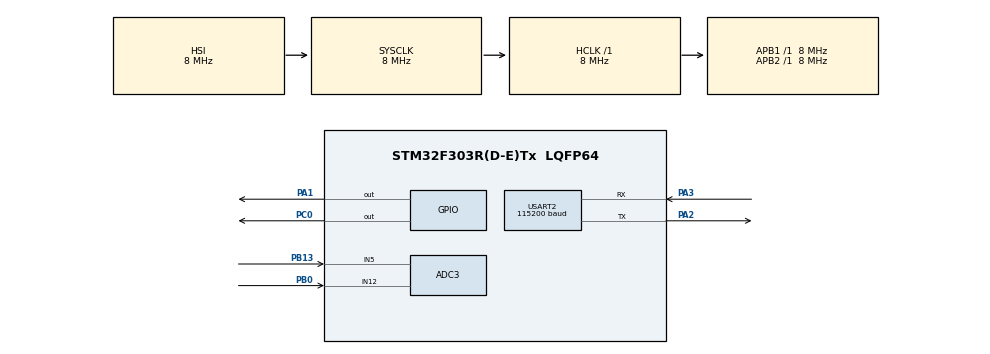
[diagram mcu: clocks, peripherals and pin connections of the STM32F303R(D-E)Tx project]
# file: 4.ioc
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ADC3.Channel-0\#ChannelRegularConversion=ADC_CHANNEL_12
ADC3.Channel-1\#ChannelRegularConversion=ADC_CHANNEL_5
ADC3.ContinuousConvMode=ENABLE
ADC3.DMAContinuousRequests=ENABLE
ADC3.NbrOfConversion=2
ADC3.NbrOfConversionFlag=1
ADC3.Offset-0\#ChannelRegularConversion=0
ADC3.Offset-1\#ChannelRegularConversion=0
ADC3.OffsetNumber-0\#ChannelRegularConversion=ADC_OFFSET_NONE
ADC3.OffsetNumber-1\#ChannelRegularConversion=ADC_OFFSET_NONE
ADC3.Rank-0\#ChannelRegularConversion=1
ADC3.Rank-1\#ChannelRegularConversion=2
ADC3.SamplingTime-0\#ChannelRegularConversion=ADC_SAMPLETIME_1CYCLE_5
ADC3.SamplingTime-1\#ChannelRegularConversion=ADC_SAMPLETIME_1CYCLE_5
ADC3.master=1
Dma.ADC3.0.Direction=DMA_PERIPH_TO_MEMORY
Dma.ADC3.0.Instance=DMA2_Channel5
Dma.ADC3.0.MemDataAlignment=DMA_MDATAALIGN_WORD
Dma.ADC3.0.MemInc=DMA_MINC_ENABLE
Dma.ADC3.0.Mode=DMA_CIRCULAR
Dma.ADC3.0.PeriphDataAlignment=DMA_PDATAALIGN_WORD
Dma.ADC3.0.PeriphInc=DMA_PINC_DISABLE
Dma.ADC3.0.Priority=DMA_PRIORITY_LOW
Dma.Request0=ADC3
Mcu.Family=STM32F3
Mcu.Name=STM32F303R(D-E)Tx
Mcu.Package=LQFP64
NVIC.DMA2_Channel5_IRQn=true\:0\:0\:false\:false\:true\:false
NVIC.PriorityGroup=NVIC_PRIORITYGROUP_4
PA1.Signal=GPIO_Output
PA2.Mode=Asynchronous
PA2.Signal=USART2_TX
PA3.Mode=Asynchronous
PA3.Signal=USART2_RX
PB0.Mode=IN12-Single-Ended
PB0.Signal=ADC3_IN12
PB13.Mode=IN5-Single-Ended
PB13.Signal=ADC3_IN5
PC0.PinState=GPIO_PIN_SET
PC0.Signal=GPIO_Output
ProjectManager.HeapSize=0x200
ProjectManager.StackSize=0x400
ProjectManager.TargetToolchain=TrueSTUDIO
RCC.ADC12PRES=RCC_ADC12PLLCLK_DIV2
RCC.ADC34PRES=RCC_ADC34PLLCLK_DIV2
RCC.AHBFreq_Value=8000000
RCC.APB1Freq_Value=8000000
RCC.APB2Freq_Value=8000000
RCC.CortexFreq_Value=8000000
RCC.HSE_VALUE=8000000
RCC.HSI_VALUE=8000000
RCC.LSE_VALUE=32768
RCC.SYSCLKFreq_VALUE=8000000
RCC.USBFreq_Value=16000000
USART2.BaudRate=115200
USART2.VirtualMode-Asynchronous=VM_ASYNC
USART2.WordLength=WORDLENGTH_8B
board=4

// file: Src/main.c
/**
  ******************************************************************************
  * @file           : main.c
  * @brief          : Main program body
  ******************************************************************************
  ** This notice applies to any and all portions of this file
  * that are not between comment pairs USER CODE BEGIN and
  * USER CODE END. Other portions of this file, whether
  * inserted by the user or by software development tools
  * are owned by their respective copyright owners.
  *
  * COPYRIGHT(c) 2018 STMicroelectronics
  *
  * Redistribution and use in source and binary forms, with or without modification,
  * are permitted provided that the following conditions are met:
  *   1. Redistributions of source code must retain the above copyright notice,
  *      this list of conditions and the following disclaimer.
  *   2. Redistributions in binary form must reproduce the above copyright notice,
  *      this list of conditions and the following disclaimer in the documentation
  *      and/or other materials provided with the distribution.
  *   3. Neither the name of STMicroelectronics nor the names of its contributors
  *      may be used to endorse or promote products derived from this software
  *      without specific prior written permission.
  *
  * THIS SOFTWARE IS PROVIDED BY THE COPYRIGHT HOLDERS AND CONTRIBUTORS "AS IS"
  * AND ANY EXPRESS OR IMPLIED WARRANTIES, INCLUDING, BUT NOT LIMITED TO, THE
  * IMPLIED WARRANTIES OF MERCHANTABILITY AND FITNESS FOR A PARTICULAR PURPOSE ARE
  * DISCLAIMED. IN NO EVENT SHALL THE COPYRIGHT HOLDER OR CONTRIBUTORS BE LIABLE
  * FOR ANY DIRECT, INDIRECT, INCIDENTAL, SPECIAL, EXEMPLARY, OR CONSEQUENTIAL
  * DAMAGES (INCLUDING, BUT NOT LIMITED TO, PROCUREMENT OF SUBSTITUTE GOODS OR
  * SERVICES; LOSS OF USE, DATA, OR PROFITS; OR BUSINESS INTERRUPTION) HOWEVER
  * CAUSED AND ON ANY THEORY OF LIABILITY, WHETHER IN CONTRACT, STRICT LIABILITY,
  * OR TORT (INCLUDING NEGLIGENCE OR OTHERWISE) ARISING IN ANY WAY OUT OF THE USE
  * OF THIS SOFTWARE, EVEN IF ADVISED OF THE POSSIBILITY OF SUCH DAMAGE.
  *
  ******************************************************************************
  */
#include "main.h"
#include "stm32f3xx_hal.h"

ADC_HandleTypeDef hadc3;
DMA_HandleTypeDef hdma_adc3;

UART_HandleTypeDef huart2;

/* USER CODE BEGIN PV */
/* Private variables ---------------------------------------------------------*/

/* USER CODE END PV */

void SystemClock_Config(void);
static void MX_GPIO_Init(void);
static void MX_DMA_Init(void);
static void MX_USART2_UART_Init(void);
static void MX_ADC3_Init(void);

/* USER CODE BEGIN PFP */
/* Private function prototypes -----------------------------------------------*/
uint32_t adc_buf[2];
/* USER CODE END PFP */

int main(void)
{

  /* MCU Configuration----------------------------------------------------------*/

  /* Reset of all peripherals, Initializes the Flash interface and the Systick. */
  HAL_Init();

  /* Configure the system clock */
  SystemClock_Config();

  /* Initialize all configured peripherals */
  MX_GPIO_Init();
  MX_DMA_Init();
  MX_USART2_UART_Init();
  MX_ADC3_Init();
  /* USER CODE BEGIN 2 */
//  uint32_t adc_buf[2];

  HAL_StatusTypeDef status=HAL_ADC_Start_DMA(&hadc3,adc_buf,2);

  /* USER CODE END 2 */

  /* Infinite loop */
  while (1)
  {
  }

}

void SystemClock_Config(void)
{

  RCC_OscInitTypeDef RCC_OscInitStruct;
  RCC_ClkInitTypeDef RCC_ClkInitStruct;
  RCC_PeriphCLKInitTypeDef PeriphClkInit;

    /**Initializes the CPU, AHB and APB busses clocks
    */
  RCC_OscInitStruct.OscillatorType = RCC_OSCILLATORTYPE_HSI;
  RCC_OscInitStruct.HSIState = RCC_HSI_ON;
  RCC_OscInitStruct.HSICalibrationValue = 16;
  RCC_OscInitStruct.PLL.PLLState = RCC_PLL_ON;
  RCC_OscInitStruct.PLL.PLLSource = RCC_PLLSOURCE_HSI;
  RCC_OscInitStruct.PLL.PLLMUL = RCC_PLL_MUL2;
  RCC_OscInitStruct.PLL.PREDIV = RCC_PREDIV_DIV1;
  if (HAL_RCC_OscConfig(&RCC_OscInitStruct) != HAL_OK)
  {
    _Error_Handler(__FILE__, __LINE__);
  }

    /**Initializes the CPU, AHB and APB busses clocks
    */
  RCC_ClkInitStruct.ClockType = RCC_CLOCKTYPE_HCLK|RCC_CLOCKTYPE_SYSCLK
                              |RCC_CLOCKTYPE_PCLK1|RCC_CLOCKTYPE_PCLK2;
  RCC_ClkInitStruct.SYSCLKSource = RCC_SYSCLKSOURCE_HSI;
  RCC_ClkInitStruct.AHBCLKDivider = RCC_SYSCLK_DIV1;
  RCC_ClkInitStruct.APB1CLKDivider = RCC_HCLK_DIV1;
  RCC_ClkInitStruct.APB2CLKDivider = RCC_HCLK_DIV1;

  if (HAL_RCC_ClockConfig(&RCC_ClkInitStruct, FLASH_LATENCY_0) != HAL_OK)
  {
    _Error_Handler(__FILE__, __LINE__);
  }

  PeriphClkInit.PeriphClockSelection = RCC_PERIPHCLK_USART2|RCC_PERIPHCLK_ADC34;
  PeriphClkInit.Usart2ClockSelection = RCC_USART2CLKSOURCE_PCLK1;
  PeriphClkInit.Adc34ClockSelection = RCC_ADC34PLLCLK_DIV2;
  if (HAL_RCCEx_PeriphCLKConfig(&PeriphClkInit) != HAL_OK)
  {
    _Error_Handler(__FILE__, __LINE__);
  }

    /**Configure the Systick interrupt time
    */
  HAL_SYSTICK_Config(HAL_RCC_GetHCLKFreq()/1000);

    /**Configure the Systick
    */
  HAL_SYSTICK_CLKSourceConfig(SYSTICK_CLKSOURCE_HCLK);

  /* SysTick_IRQn interrupt configuration */
  HAL_NVIC_SetPriority(SysTick_IRQn, 0, 0);
}

/* ADC3 init function */
static void MX_ADC3_Init(void)
{

  ADC_MultiModeTypeDef multimode;
  ADC_ChannelConfTypeDef sConfig;

    /**Common config
    */
  hadc3.Instance = ADC3;
  hadc3.Init.ClockPrescaler = ADC_CLOCK_ASYNC_DIV1;
  hadc3.Init.Resolution = ADC_RESOLUTION_12B;
  hadc3.Init.ScanConvMode = ADC_SCAN_ENABLE;
  hadc3.Init.ContinuousConvMode = ENABLE;
  hadc3.Init.DiscontinuousConvMode = DISABLE;
  hadc3.Init.ExternalTrigConvEdge = ADC_EXTERNALTRIGCONVEDGE_NONE;
  hadc3.Init.ExternalTrigConv = ADC_SOFTWARE_START;
  hadc3.Init.DataAlign = ADC_DATAALIGN_RIGHT;
  hadc3.Init.NbrOfConversion = 2;
  hadc3.Init.DMAContinuousRequests = ENABLE;
  hadc3.Init.EOCSelection = ADC_EOC_SINGLE_CONV;
  hadc3.Init.LowPowerAutoWait = DISABLE;
  hadc3.Init.Overrun = ADC_OVR_DATA_OVERWRITTEN;
  if (HAL_ADC_Init(&hadc3) != HAL_OK)
  {
    _Error_Handler(__FILE__, __LINE__);
  }

    /**Configure the ADC multi-mode
    */
  multimode.Mode = ADC_MODE_INDEPENDENT;
  if (HAL_ADCEx_MultiModeConfigChannel(&hadc3, &multimode) != HAL_OK)
  {
    _Error_Handler(__FILE__, __LINE__);
  }

    /**Configure Regular Channel
    */
  sConfig.Channel = ADC_CHANNEL_12;
  sConfig.Rank = ADC_REGULAR_RANK_1;
  sConfig.SingleDiff = ADC_SINGLE_ENDED;
  sConfig.SamplingTime = ADC_SAMPLETIME_1CYCLE_5;
  sConfig.OffsetNumber = ADC_OFFSET_NONE;
  sConfig.Offset = 0;
  if (HAL_ADC_ConfigChannel(&hadc3, &sConfig) != HAL_OK)
  {
    _Error_Handler(__FILE__, __LINE__);
  }

    /**Configure Regular Channel
    */
  sConfig.Channel = ADC_CHANNEL_5;
  sConfig.Rank = ADC_REGULAR_RANK_2;
  if (HAL_ADC_ConfigChannel(&hadc3, &sConfig) != HAL_OK)
  {
    _Error_Handler(__FILE__, __LINE__);
  }

}

/* USART2 init function */
static void MX_USART2_UART_Init(void)
{

  huart2.Instance = USART2;
  huart2.Init.BaudRate = 115200;
  huart2.Init.WordLength = UART_WORDLENGTH_8B;
  huart2.Init.StopBits = UART_STOPBITS_1;
  huart2.Init.Parity = UART_PARITY_NONE;
  huart2.Init.Mode = UART_MODE_TX_RX;
  huart2.Init.HwFlowCtl = UART_HWCONTROL_NONE;
  huart2.Init.OverSampling = UART_OVERSAMPLING_16;
  huart2.Init.OneBitSampling = UART_ONE_BIT_SAMPLE_DISABLE;
  huart2.AdvancedInit.AdvFeatureInit = UART_ADVFEATURE_NO_INIT;
  if (HAL_UART_Init(&huart2) != HAL_OK)
  {
    _Error_Handler(__FILE__, __LINE__);
  }

}

static void MX_DMA_Init(void)
{
  /* DMA controller clock enable */
  __HAL_RCC_DMA2_CLK_ENABLE();

  /* DMA interrupt init */
  /* DMA2_Channel5_IRQn interrupt configuration */
  HAL_NVIC_SetPriority(DMA2_Channel5_IRQn, 0, 0);
  HAL_NVIC_EnableIRQ(DMA2_Channel5_IRQn);

}

/** Configure pins as
        * Analog
        * Input
        * Output
        * EVENT_OUT
        * EXTI
*/
static void MX_GPIO_Init(void)
{

  GPIO_InitTypeDef GPIO_InitStruct;

  /* GPIO Ports Clock Enable */
  __HAL_RCC_GPIOC_CLK_ENABLE();
  __HAL_RCC_GPIOA_CLK_ENABLE();
  __HAL_RCC_GPIOB_CLK_ENABLE();

  /*Configure GPIO pin Output Level */
  HAL_GPIO_WritePin(GPIOC, GPIO_PIN_0, GPIO_PIN_SET);

  /*Configure GPIO pin Output Level */
  HAL_GPIO_WritePin(GPIOA, GPIO_PIN_1, GPIO_PIN_RESET);

  /*Configure GPIO pin : PC0 */
  GPIO_InitStruct.Pin = GPIO_PIN_0;
  GPIO_InitStruct.Mode = GPIO_MODE_OUTPUT_PP;
  GPIO_InitStruct.Pull = GPIO_NOPULL;
  GPIO_InitStruct.Speed = GPIO_SPEED_FREQ_LOW;
  HAL_GPIO_Init(GPIOC, &GPIO_InitStruct);

  /*Configure GPIO pins : PA1 */
  GPIO_InitStruct.Pin = GPIO_PIN_1;
  GPIO_InitStruct.Mode = GPIO_MODE_OUTPUT_PP;
  GPIO_InitStruct.Pull = GPIO_NOPULL;
  GPIO_InitStruct.Speed = GPIO_SPEED_FREQ_LOW;
  HAL_GPIO_Init(GPIOA, &GPIO_InitStruct);

}

void _Error_Handler(char *file, int line)
{
  while(1)
  {
  }
}

/************************ (C) COPYRIGHT STMicroelectronics *****END OF FILE****/
